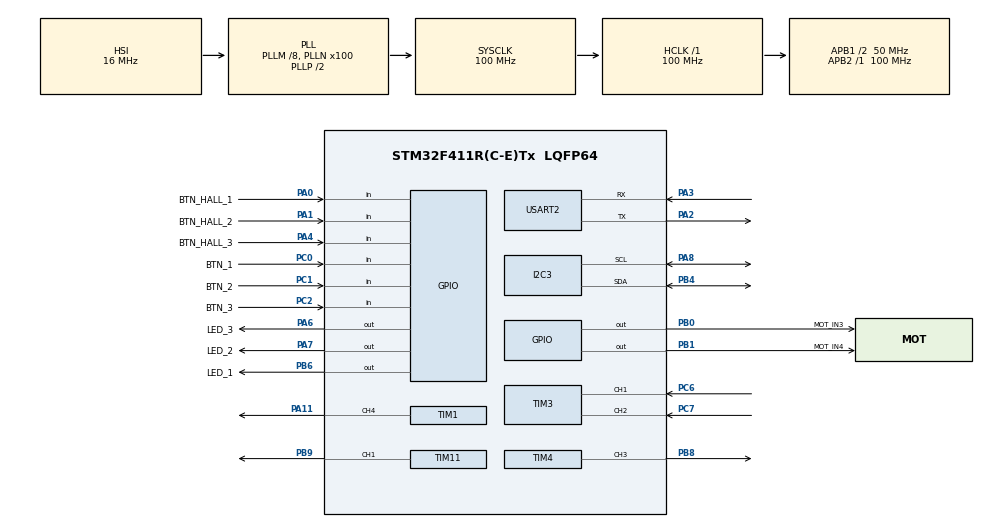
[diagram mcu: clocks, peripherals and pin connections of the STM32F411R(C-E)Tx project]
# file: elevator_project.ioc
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Mcu.Family=STM32F4
Mcu.Name=STM32F411R(C-E)Tx
Mcu.Package=LQFP64
NVIC.PriorityGroup=NVIC_PRIORITYGROUP_4
PA0-WKUP.GPIO_Label=BTN_HALL_1
PA0-WKUP.GPIO_PuPd=GPIO_PULLUP
PA0-WKUP.Signal=GPIO_Input
PA1.GPIO_Label=BTN_HALL_2
PA1.GPIO_PuPd=GPIO_PULLUP
PA1.Signal=GPIO_Input
PA11.Signal=S_TIM1_CH4
PA13.Mode=Serial_Wire
PA13.Signal=SYS_JTMS-SWDIO
PA14.Mode=Serial_Wire
PA14.Signal=SYS_JTCK-SWCLK
PA2.Mode=Asynchronous
PA2.Signal=USART2_TX
PA3.Mode=Asynchronous
PA3.Signal=USART2_RX
PA4.GPIO_Label=BTN_HALL_3
PA4.GPIO_PuPd=GPIO_PULLUP
PA4.Signal=GPIO_Input
PA6.GPIO_Label=LED_3
PA6.Signal=GPIO_Output
PA7.GPIO_Label=LED_2
PA7.Signal=GPIO_Output
PA8.Mode=I2C
PA8.Signal=I2C3_SCL
PB0.GPIO_Label=MOT_IN3
PB0.Signal=GPIO_Output
PB1.GPIO_Label=MOT_IN4
PB1.Signal=GPIO_Output
PB4.Mode=I2C
PB4.Signal=I2C3_SDA
PB6.GPIO_Label=LED_1
PB6.Signal=GPIO_Output
PB8.Signal=S_TIM4_CH3
PB9.Signal=S_TIM11_CH1
PC0.GPIO_Label=BTN_1
PC0.GPIO_PuPd=GPIO_PULLUP
PC0.Signal=GPIO_Input
PC1.GPIO_Label=BTN_2
PC1.GPIO_PuPd=GPIO_PULLUP
PC1.Signal=GPIO_Input
PC2.GPIO_Label=BTN_3
PC2.GPIO_PuPd=GPIO_PULLUP
PC2.Signal=GPIO_Input
PC6.GPIO_PuPd=GPIO_PULLUP
PC6.Signal=S_TIM3_CH1
PC7.GPIO_PuPd=GPIO_PULLUP
PC7.Signal=S_TIM3_CH2
PH0\ -\ OSC_IN.Mode=HSE-External-Clock-Source
PH0\ -\ OSC_IN.Signal=RCC_OSC_IN
PH1\ -\ OSC_OUT.Mode=HSE-External-Clock-Source
PH1\ -\ OSC_OUT.Signal=RCC_OSC_OUT
ProjectManager.HeapSize=0x200
ProjectManager.StackSize=0x400
ProjectManager.TargetToolchain=CMake
RCC.48MHZClocksFreq_Value=50000000
RCC.AHBFreq_Value=100000000
RCC.APB1CLKDivider=RCC_HCLK_DIV2
RCC.APB1Freq_Value=50000000
RCC.APB1TimFreq_Value=100000000
RCC.APB2Freq_Value=100000000
RCC.APB2TimFreq_Value=100000000
RCC.CortexFreq_Value=100000000
RCC.HCLKFreq_Value=100000000
RCC.HSE_VALUE=25000000
RCC.HSI_VALUE=16000000
RCC.LSE_VALUE=32768
RCC.PLLM=8
RCC.PLLN=100
RCC.SYSCLKFreq_VALUE=100000000
RCC.SYSCLKSource=RCC_SYSCLKSOURCE_PLLCLK
RCC.VCOOutputFreq_Value=200000000
SH.S_TIM11_CH1.0=TIM11_CH1,PWM Generation1 CH1
SH.S_TIM1_CH4.0=TIM1_CH4,PWM Generation4 CH4
SH.S_TIM3_CH1.0=TIM3_CH1,Encoder_Interface
SH.S_TIM3_CH2.0=TIM3_CH2,Encoder_Interface
SH.S_TIM4_CH3.0=TIM4_CH3,PWM Generation3 CH3
TIM1.Channel-PWM\ Generation4\ CH4=TIM_CHANNEL_4
TIM1.Period=20000-1
TIM1.Prescaler=840-1
TIM11.Channel=TIM_CHANNEL_1
TIM11.Period=1000-1
TIM11.Prescaler=100-1
TIM3.IC1Filter=5
TIM3.IC2Filter=5
TIM4.Channel-PWM\ Generation3\ CH3=TIM_CHANNEL_3
TIM4.Period=1000-1
TIM4.Prescaler=100-1
USART2.VirtualMode=VM_ASYNC
VP_TIM11_VS_ClockSourceINT.Mode=Enable_Timer
VP_TIM1_VS_ClockSourceINT.Mode=Internal
board=custom

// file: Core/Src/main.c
/* USER CODE BEGIN Header */
/**
  ******************************************************************************
  * @file           : main.c
  * @brief          : Main program body
  ******************************************************************************
  * @attention
  *
  * Copyright (c) 2026 STMicroelectronics.
  * All rights reserved.
  *
  * This software is licensed under terms that can be found in the LICENSE file
  * in the root directory of this software component.
  * If no LICENSE file comes with this software, it is provided AS-IS.
  *
  ******************************************************************************
  */
/* USER CODE END Header */
#include "main.h"
#include "i2c.h"
#include "tim.h"
#include "usart.h"
#include "gpio.h"

/* USER CODE BEGIN Includes */
#include "appMain.h"
/* USER CODE END Includes */

void SystemClock_Config(void);

int main(void)
{

  /* MCU Configuration--------------------------------------------------------*/

  /* Reset of all peripherals, Initializes the Flash interface and the Systick. */
  HAL_Init();

  /* Configure the system clock */
  SystemClock_Config();

  /* Initialize all configured peripherals */
  MX_GPIO_Init();
  MX_TIM4_Init();
  MX_I2C3_Init();
  MX_TIM1_Init();
  MX_TIM3_Init();
  MX_TIM11_Init();
  MX_USART2_UART_Init();
  /* USER CODE BEGIN 2 */

  appInit();
  appTestDoor();
  // appTestMotor();
  // appTestFloorSensor();

  /* USER CODE END 2 */

  /* Infinite loop */
  while (1)
  {

    /* USER CODE BEGIN 3 */
    appRun();
  }
  /* USER CODE END 3 */
}

void SystemClock_Config(void)
{
  RCC_OscInitTypeDef RCC_OscInitStruct = {0};
  RCC_ClkInitTypeDef RCC_ClkInitStruct = {0};

  /** Configure the main internal regulator output voltage
  */
  __HAL_RCC_PWR_CLK_ENABLE();
  __HAL_PWR_VOLTAGESCALING_CONFIG(PWR_REGULATOR_VOLTAGE_SCALE1);

  /** Initializes the RCC Oscillators according to the specified parameters
  * in the RCC_OscInitTypeDef structure.
  */
  RCC_OscInitStruct.OscillatorType = RCC_OSCILLATORTYPE_HSI;
  RCC_OscInitStruct.HSIState = RCC_HSI_ON;
  RCC_OscInitStruct.HSICalibrationValue = RCC_HSICALIBRATION_DEFAULT;
  RCC_OscInitStruct.PLL.PLLState = RCC_PLL_ON;
  RCC_OscInitStruct.PLL.PLLSource = RCC_PLLSOURCE_HSI;
  RCC_OscInitStruct.PLL.PLLM = 8;
  RCC_OscInitStruct.PLL.PLLN = 100;
  RCC_OscInitStruct.PLL.PLLP = RCC_PLLP_DIV2;
  RCC_OscInitStruct.PLL.PLLQ = 4;
  if (HAL_RCC_OscConfig(&RCC_OscInitStruct) != HAL_OK)
  {
    Error_Handler();
  }

  /** Initializes the CPU, AHB and APB buses clocks
  */
  RCC_ClkInitStruct.ClockType = RCC_CLOCKTYPE_HCLK|RCC_CLOCKTYPE_SYSCLK
                              |RCC_CLOCKTYPE_PCLK1|RCC_CLOCKTYPE_PCLK2;
  RCC_ClkInitStruct.SYSCLKSource = RCC_SYSCLKSOURCE_PLLCLK;
  RCC_ClkInitStruct.AHBCLKDivider = RCC_SYSCLK_DIV1;
  RCC_ClkInitStruct.APB1CLKDivider = RCC_HCLK_DIV2;
  RCC_ClkInitStruct.APB2CLKDivider = RCC_HCLK_DIV1;

  if (HAL_RCC_ClockConfig(&RCC_ClkInitStruct, FLASH_LATENCY_3) != HAL_OK)
  {
    Error_Handler();
  }
}

void Error_Handler(void)
{
  __disable_irq();
  while (1)
  {
  }
}
